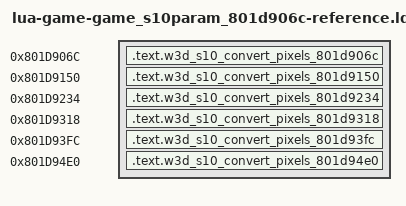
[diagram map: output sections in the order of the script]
/* Generated reference-only placements. All bodies are source-built. */
OUTPUT_FORMAT("elf32-powerpc")
OUTPUT_ARCH(powerpc)
ENTRY(w3d_s10_convert_pixels_801d906c)
_SDA_BASE_ = 0x804b2540;
_SDA2_BASE_ = 0x804c2540;
lbl_803af6e4 = 0x803af6e4;
lbl_803af6ec = 0x803af6ec;
lbl_803af6f4 = 0x803af6f4;
lbl_803af6fc = 0x803af6fc;
lbl_803af704 = 0x803af704;
lbl_803af70c = 0x803af70c;
SECTIONS {
  .text.w3d_s10_convert_pixels_801d906c 0x801d906c : { *(.text.w3d_s10_convert_pixels_801d906c) }
  .text.w3d_s10_convert_pixels_801d9150 0x801d9150 : { *(.text.w3d_s10_convert_pixels_801d9150) }
  .text.w3d_s10_convert_pixels_801d9234 0x801d9234 : { *(.text.w3d_s10_convert_pixels_801d9234) }
  .text.w3d_s10_convert_pixels_801d9318 0x801d9318 : { *(.text.w3d_s10_convert_pixels_801d9318) }
  .text.w3d_s10_convert_pixels_801d93fc 0x801d93fc : { *(.text.w3d_s10_convert_pixels_801d93fc) }
  .text.w3d_s10_convert_pixels_801d94e0 0x801d94e0 : { *(.text.w3d_s10_convert_pixels_801d94e0) }
  /DISCARD/ : { *(.text*) *(.rodata*) *(.data*) *(.bss*) *(.sdata*) *(.sbss*) *(.comment) }
}
